# MSP430FR5969 register map
Vendor: msp430gen; File version: v0.4.0-24-gb954137
Registers are 16-bit, read-write, reset 0x0 unless marked. A register's access mark holds for its fields unless they carry their own. Offsets are from the block's base; [hi:lo] are bit positions; {n}, {i} and the like mark numbered series.

## USCI_B0_SPI_MODE
Base 0x00000640
0x00 UCB0CTL1_SPI 8-bit — USCI B0 Control Register 1
0x01 UCB0CTL0_SPI 8-bit — USCI B0 Control Register 0
0x06 UCB0BR0_SPI 8-bit — USCI B0 Baud Rate 0
0x07 UCB0BR1_SPI 8-bit — USCI B0 Baud Rate 1
0x0C UCB0RXBUF_SPI — USCI B0 Receive Buffer
0x0E UCB0TXBUF_SPI — USCI B0 Transmit Buffer
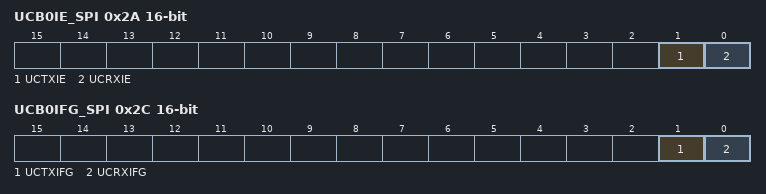
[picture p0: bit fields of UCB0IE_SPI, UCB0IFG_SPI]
0x2A UCB0IE_SPI — USCI B0 Interrupt Enable Register
  [1] UCTXIE — USCI Transmit Interrupt Enable
  [0] UCRXIE — USCI Receive Interrupt Enable
0x2C UCB0IFG_SPI — USCI B0 Interrupt Flags Register
  [1] UCTXIFG — SPI Transmit Interrupt Flag
  [0] UCRXIFG — SPI Receive Interrupt Flag
0x2E UCB0IV_SPI — USCI B0 Interrupt Vector Register

## SFR — SFR Special Function Registers
Base 0x00000100
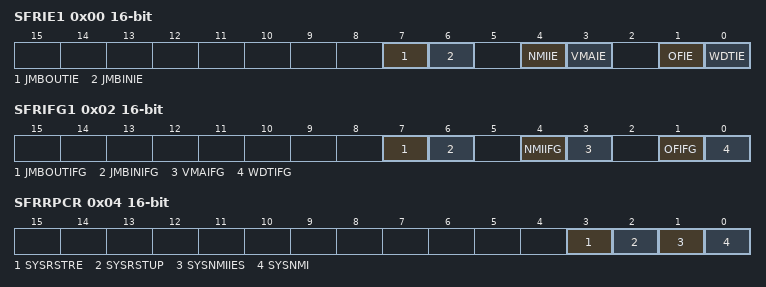
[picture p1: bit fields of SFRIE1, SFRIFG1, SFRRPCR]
0x00 SFRIE1 — Interrupt Enable 1
  [7] JMBOUTIE — JTAG Mail Box output Interrupt Enable
  [6] JMBINIE — JTAG Mail Box input Interrupt Enable
  [4] NMIIE — NMI Interrupt Enable
  [3] VMAIE — Vacant Memory Interrupt Enable
  [1] OFIE — Osc Fault Enable
  [0] WDTIE — WDT Interrupt Enable
0x02 SFRIFG1 — Interrupt Flag 1
  [7] JMBOUTIFG — JTAG Mail Box output Interrupt Flag
  [6] JMBINIFG — JTAG Mail Box input Interrupt Flag
  [4] NMIIFG — NMI Interrupt Flag
  [3] VMAIFG — Vacant Memory Interrupt Flag
  [1] OFIFG — Osc Fault Flag
  [0] WDTIFG — WDT Interrupt Flag
0x04 SFRRPCR — RESET Pin Control Register
  [3] SYSRSTRE — RESET Pin Resistor enable
  [2] SYSRSTUP — RESET Pin pull down/up select
  [1] SYSNMIIES — NMI edge select
  [0] SYSNMI — NMI select

## PMM — PMM Power Management System
Base 0x00000120
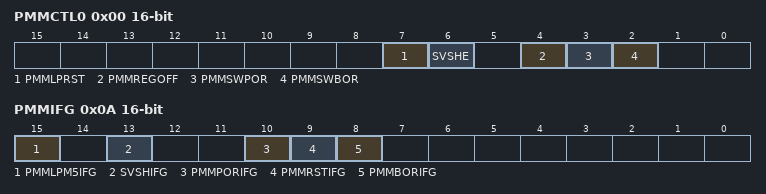
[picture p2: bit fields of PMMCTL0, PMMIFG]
0x00 PMMCTL0 — PMM Control 0
  [7] PMMLPRST — PMM Low-Power Reset Enable
  [6] SVSHE — SVS high side enable
  [4] PMMREGOFF — PMM Turn Regulator off
  [3] PMMSWPOR — PMM Software POR
  [2] PMMSWBOR — PMM Software BOR
0x0A PMMIFG — PMM Interrupt Flag
  [15] PMMLPM5IFG — LPM5 indication Flag
  [13] SVSHIFG — SVS low side interrupt flag
  [10] PMMPORIFG — PMM Software POR interrupt flag
  [9] PMMRSTIFG — PMM RESET pin interrupt flag
  [8] PMMBORIFG — PMM Software BOR interrupt flag
0x10 PM5CTL0 — PMM Power Mode 5 Control Register 0
  [0] LOCKLPM5 — Lock I/O pin configuration upon entry/exit to/from LPM5

## FRAM
Base 0x00000140
0x00 FRCTL0 — FRAM Controller Control 0
  [6:4] NWAITS — FRAM Wait state control Bit: 0
    {v}=FRAM Wait state control: {v} (v=0..7)
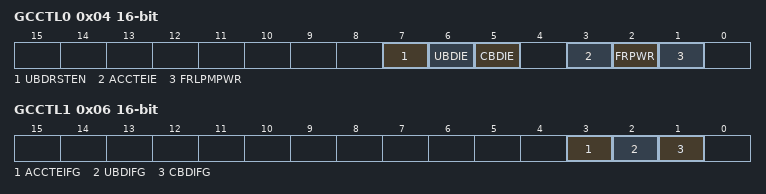
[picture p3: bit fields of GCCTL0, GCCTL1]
0x04 GCCTL0 — General Control 0
  [7] UBDRSTEN — Enable Power Up Clear (PUC) reset if FRAM uncorrectable bit error detected
  [6] UBDIE — Enable NMI event if uncorrectable bit error detected
  [5] CBDIE — Enable NMI event if correctable bit error detected
  [3] ACCTEIE — RESERVED
  [2] FRPWR — FRAM Power Control
  [1] FRLPMPWR — FRAM Enable FRAM auto power up after LPM
0x06 GCCTL1 — General Control 1
  [3] ACCTEIFG — Access time error flag
  [2] UBDIFG — FRAM uncorrectable bit error flag
  [1] CBDIFG — FRAM correctable bit error flag

## CRC16
Base 0x00000150
0x00 CRCDI — CRC Data In Register
0x02 CRCDIRB — CRC data in reverse byte Register
0x04 CRCINIRES — CRC Initialisation Register and Result Register
0x06 CRCRESR — CRC reverse result Register

## WATCHDOG_TIMER
Base 0x0000015C
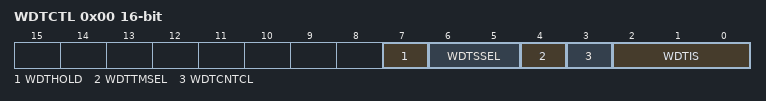
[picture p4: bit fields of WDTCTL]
0x00 WDTCTL — Watchdog Timer Control
  [7] WDTHOLD — WDT - Timer hold
  [6:5] WDTSSEL — WDT - Timer Clock Source Select 0
    0=WDT - Timer Clock Source Select: SMCLK; 1=WDT - Timer Clock Source Select: ACLK; 2=WDT - Timer Clock Source Select: VLO_CLK; 3=WDT - Timer Clock Source Select: reserved
  [4] WDTTMSEL — WDT - Timer Mode Select
  [3] WDTCNTCL — WDT - Timer Clear
  [2:0] WDTIS — WDT - Timer Interval Select 0
    0=WDT - Timer Interval Select: /2G; 1=WDT - Timer Interval Select: /128M; 2=WDT - Timer Interval Select: /8192k; 3=WDT - Timer Interval Select: /512k; 4=WDT - Timer Interval Select: /32k; 5=WDT - Timer Interval Select: /8192; 6=WDT - Timer Interval Select: /512; 7=WDT - Timer Interval Select: /64
